# ESP32-H4 register map
Vendor: ESPRESSIF SYSTEMS (SHANGHAI) CO., LTD.; Series: ESP32 H-Series; File version: 1
CPU: RV32IMAC r0p0, little endian, no MPU, no FPU, 0 interrupt priority bits
Address unit: 32 bits
Registers are 32-bit, read-write, reset 0x0 unless marked. A register's access mark holds for its fields unless they carry their own. Offsets are from the block's base; [hi:lo] are bit positions.

## LP_TEE — Low-power Trusted Execution Environment
Base 0x600B1400
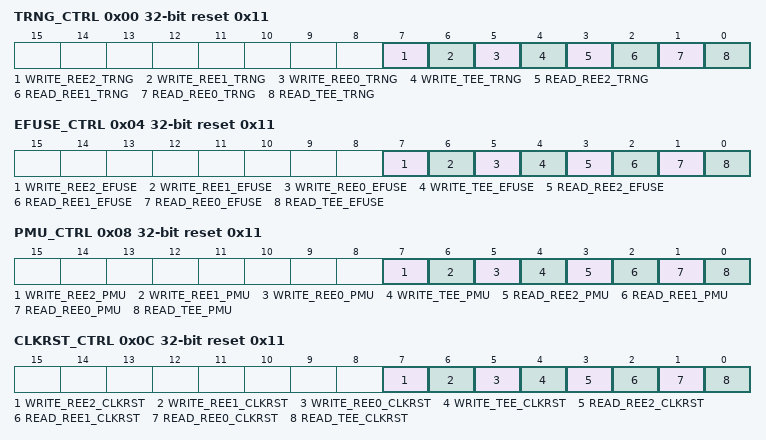
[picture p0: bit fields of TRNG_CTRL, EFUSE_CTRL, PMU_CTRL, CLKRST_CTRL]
0x00 TRNG_CTRL reset 0x11 — trng read/write control register
  [7] WRITE_REE2_TRNG — Configures trng registers write permission in ree2 mode.\\ 0: can not be write \\ 1: can be write \\
  [6] WRITE_REE1_TRNG — Configures trng registers write permission in ree1 mode.\\ 0: can not be write \\ 1: can be write \\
  [5] WRITE_REE0_TRNG — Configures trng registers write permission in ree0 mode.\\ 0: can not be write \\ 1: can be write \\
  [4] WRITE_TEE_TRNG — Configures trng registers write permission in tee mode.\\ 0: can not be write \\ 1: can be write \\
  [3] READ_REE2_TRNG — Configures trng registers read permission in ree2 mode.\\ 0: can not be read \\ 1: can be read \\
  [2] READ_REE1_TRNG — Configures trng registers read permission in ree1 mode.\\ 0: can not be read \\ 1: can be read \\
  [1] READ_REE0_TRNG — Configures trng registers read permission in ree0 mode.\\ 0: can not be read \\ 1: can be read \\
  [0] READ_TEE_TRNG — Configures trng registers read permission in tee mode.\\ 0: can not be read \\ 1: can be read \\
0x04 EFUSE_CTRL reset 0x11 — efuse read/write control register
  [7] WRITE_REE2_EFUSE — Configures efuse registers write permission in ree2 mode.\\ 0: can not be write \\ 1: can be write \\
  [6] WRITE_REE1_EFUSE — Configures efuse registers write permission in ree1 mode.\\ 0: can not be write \\ 1: can be write \\
  [5] WRITE_REE0_EFUSE — Configures efuse registers write permission in ree0 mode.\\ 0: can not be write \\ 1: can be write \\
  [4] WRITE_TEE_EFUSE — Configures efuse registers write permission in tee mode.\\ 0: can not be write \\ 1: can be write \\
  [3] READ_REE2_EFUSE — Configures efuse registers read permission in ree2 mode.\\ 0: can not be read \\ 1: can be read \\
  [2] READ_REE1_EFUSE — Configures efuse registers read permission in ree1 mode.\\ 0: can not be read \\ 1: can be read \\
  [1] READ_REE0_EFUSE — Configures efuse registers read permission in ree0 mode.\\ 0: can not be read \\ 1: can be read \\
  [0] READ_TEE_EFUSE — Configures efuse registers read permission in tee mode.\\ 0: can not be read \\ 1: can be read \\
0x08 PMU_CTRL reset 0x11 — pmu read/write control register
  [7] WRITE_REE2_PMU — Configures pmu registers write permission in ree2 mode.\\ 0: can not be write \\ 1: can be write \\
  [6] WRITE_REE1_PMU — Configures pmu registers write permission in ree1 mode.\\ 0: can not be write \\ 1: can be write \\
  [5] WRITE_REE0_PMU — Configures pmu registers write permission in ree0 mode.\\ 0: can not be write \\ 1: can be write \\
  [4] WRITE_TEE_PMU — Configures pmu registers write permission in tee mode.\\ 0: can not be write \\ 1: can be write \\
  [3] READ_REE2_PMU — Configures pmu registers read permission in ree2 mode.\\ 0: can not be read \\ 1: can be read \\
  [2] READ_REE1_PMU — Configures pmu registers read permission in ree1 mode.\\ 0: can not be read \\ 1: can be read \\
  [1] READ_REE0_PMU — Configures pmu registers read permission in ree0 mode.\\ 0: can not be read \\ 1: can be read \\
  [0] READ_TEE_PMU — Configures pmu registers read permission in tee mode.\\ 0: can not be read \\ 1: can be read \\
0x0C CLKRST_CTRL reset 0x11 — clkrst read/write control register
  [7] WRITE_REE2_CLKRST — Configures clkrst registers write permission in ree2 mode.\\ 0: can not be write \\ 1: can be write \\
  [6] WRITE_REE1_CLKRST — Configures clkrst registers write permission in ree1 mode.\\ 0: can not be write \\ 1: can be write \\
  [5] WRITE_REE0_CLKRST — Configures clkrst registers write permission in ree0 mode.\\ 0: can not be write \\ 1: can be write \\
  [4] WRITE_TEE_CLKRST — Configures clkrst registers write permission in tee mode.\\ 0: can not be write \\ 1: can be write \\
  [3] READ_REE2_CLKRST — Configures clkrst registers read permission in ree2 mode.\\ 0: can not be read \\ 1: can be read \\
  [2] READ_REE1_CLKRST — Configures clkrst registers read permission in ree1 mode.\\ 0: can not be read \\ 1: can be read \\
  [1] READ_REE0_CLKRST — Configures clkrst registers read permission in ree0 mode.\\ 0: can not be read \\ 1: can be read \\
  [0] READ_TEE_CLKRST — Configures clkrst registers read permission in tee mode.\\ 0: can not be read \\ 1: can be read \\
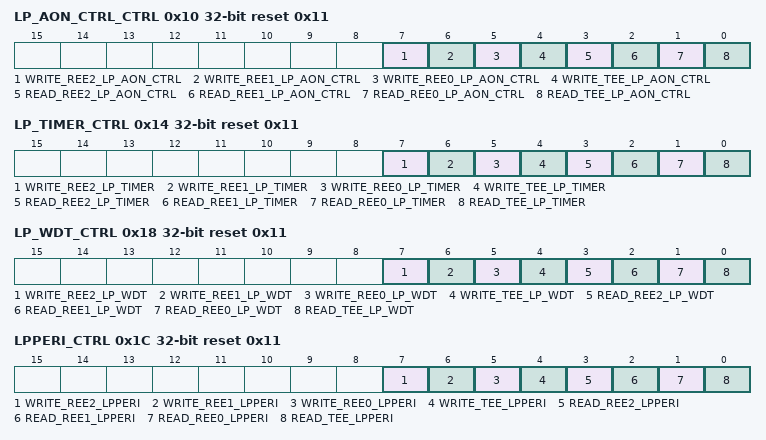
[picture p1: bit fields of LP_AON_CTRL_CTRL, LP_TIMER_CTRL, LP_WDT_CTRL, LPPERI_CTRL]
0x10 LP_AON_CTRL_CTRL reset 0x11 — lp_aon_ctrl read/write control register
  [7] WRITE_REE2_LP_AON_CTRL — Configures lp_aon_ctrl registers write permission in ree2 mode.\\ 0: can not be write \\ 1: can be write \\
  [6] WRITE_REE1_LP_AON_CTRL — Configures lp_aon_ctrl registers write permission in ree1 mode.\\ 0: can not be write \\ 1: can be write \\
  [5] WRITE_REE0_LP_AON_CTRL — Configures lp_aon_ctrl registers write permission in ree0 mode.\\ 0: can not be write \\ 1: can be write \\
  [4] WRITE_TEE_LP_AON_CTRL — Configures lp_aon_ctrl registers write permission in tee mode.\\ 0: can not be write \\ 1: can be write \\
  [3] READ_REE2_LP_AON_CTRL — Configures lp_aon_ctrl registers read permission in ree2 mode.\\ 0: can not be read \\ 1: can be read \\
  [2] READ_REE1_LP_AON_CTRL — Configures lp_aon_ctrl registers read permission in ree1 mode.\\ 0: can not be read \\ 1: can be read \\
  [1] READ_REE0_LP_AON_CTRL — Configures lp_aon_ctrl registers read permission in ree0 mode.\\ 0: can not be read \\ 1: can be read \\
  [0] READ_TEE_LP_AON_CTRL — Configures lp_aon_ctrl registers read permission in tee mode.\\ 0: can not be read \\ 1: can be read \\
0x14 LP_TIMER_CTRL reset 0x11 — lp_timer read/write control register
  [7] WRITE_REE2_LP_TIMER — Configures lp_timer registers write permission in ree2 mode.\\ 0: can not be write \\ 1: can be write \\
  [6] WRITE_REE1_LP_TIMER — Configures lp_timer registers write permission in ree1 mode.\\ 0: can not be write \\ 1: can be write \\
  [5] WRITE_REE0_LP_TIMER — Configures lp_timer registers write permission in ree0 mode.\\ 0: can not be write \\ 1: can be write \\
  [4] WRITE_TEE_LP_TIMER — Configures lp_timer registers write permission in tee mode.\\ 0: can not be write \\ 1: can be write \\
  [3] READ_REE2_LP_TIMER — Configures lp_timer registers read permission in ree2 mode.\\ 0: can not be read \\ 1: can be read \\
  [2] READ_REE1_LP_TIMER — Configures lp_timer registers read permission in ree1 mode.\\ 0: can not be read \\ 1: can be read \\
  [1] READ_REE0_LP_TIMER — Configures lp_timer registers read permission in ree0 mode.\\ 0: can not be read \\ 1: can be read \\
  [0] READ_TEE_LP_TIMER — Configures lp_timer registers read permission in tee mode.\\ 0: can not be read \\ 1: can be read \\
0x18 LP_WDT_CTRL reset 0x11 — lp_wdt read/write control register
  [7] WRITE_REE2_LP_WDT — Configures lp_wdt registers write permission in ree2 mode.\\ 0: can not be write \\ 1: can be write \\
  [6] WRITE_REE1_LP_WDT — Configures lp_wdt registers write permission in ree1 mode.\\ 0: can not be write \\ 1: can be write \\
  [5] WRITE_REE0_LP_WDT — Configures lp_wdt registers write permission in ree0 mode.\\ 0: can not be write \\ 1: can be write \\
  [4] WRITE_TEE_LP_WDT — Configures lp_wdt registers write permission in tee mode.\\ 0: can not be write \\ 1: can be write \\
  [3] READ_REE2_LP_WDT — Configures lp_wdt registers read permission in ree2 mode.\\ 0: can not be read \\ 1: can be read \\
  [2] READ_REE1_LP_WDT — Configures lp_wdt registers read permission in ree1 mode.\\ 0: can not be read \\ 1: can be read \\
  [1] READ_REE0_LP_WDT — Configures lp_wdt registers read permission in ree0 mode.\\ 0: can not be read \\ 1: can be read \\
  [0] READ_TEE_LP_WDT — Configures lp_wdt registers read permission in tee mode.\\ 0: can not be read \\ 1: can be read \\
0x1C LPPERI_CTRL reset 0x11 — lpperi read/write control register
  [7] WRITE_REE2_LPPERI — Configures lpperi registers write permission in ree2 mode.\\ 0: can not be write \\ 1: can be write \\
  [6] WRITE_REE1_LPPERI — Configures lpperi registers write permission in ree1 mode.\\ 0: can not be write \\ 1: can be write \\
  [5] WRITE_REE0_LPPERI — Configures lpperi registers write permission in ree0 mode.\\ 0: can not be write \\ 1: can be write \\
  [4] WRITE_TEE_LPPERI — Configures lpperi registers write permission in tee mode.\\ 0: can not be write \\ 1: can be write \\
  [3] READ_REE2_LPPERI — Configures lpperi registers read permission in ree2 mode.\\ 0: can not be read \\ 1: can be read \\
  [2] READ_REE1_LPPERI — Configures lpperi registers read permission in ree1 mode.\\ 0: can not be read \\ 1: can be read \\
  [1] READ_REE0_LPPERI — Configures lpperi registers read permission in ree0 mode.\\ 0: can not be read \\ 1: can be read \\
  [0] READ_TEE_LPPERI — Configures lpperi registers read permission in tee mode.\\ 0: can not be read \\ 1: can be read \\
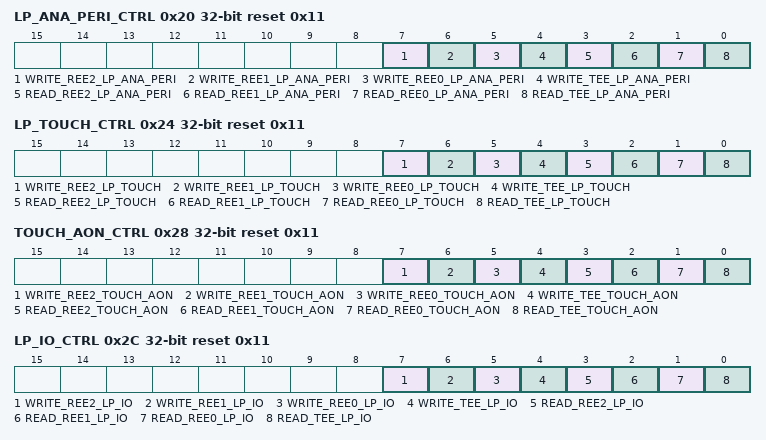
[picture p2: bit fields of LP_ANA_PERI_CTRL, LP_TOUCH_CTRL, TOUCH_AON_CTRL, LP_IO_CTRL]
0x20 LP_ANA_PERI_CTRL reset 0x11 — lp_ana_peri read/write control register
  [7] WRITE_REE2_LP_ANA_PERI — Configures lp_ana_peri registers write permission in ree2 mode.\\ 0: can not be write \\ 1: can be write \\
  [6] WRITE_REE1_LP_ANA_PERI — Configures lp_ana_peri registers write permission in ree1 mode.\\ 0: can not be write \\ 1: can be write \\
  [5] WRITE_REE0_LP_ANA_PERI — Configures lp_ana_peri registers write permission in ree0 mode.\\ 0: can not be write \\ 1: can be write \\
  [4] WRITE_TEE_LP_ANA_PERI — Configures lp_ana_peri registers write permission in tee mode.\\ 0: can not be write \\ 1: can be write \\
  [3] READ_REE2_LP_ANA_PERI — Configures lp_ana_peri registers read permission in ree2 mode.\\ 0: can not be read \\ 1: can be read \\
  [2] READ_REE1_LP_ANA_PERI — Configures lp_ana_peri registers read permission in ree1 mode.\\ 0: can not be read \\ 1: can be read \\
  [1] READ_REE0_LP_ANA_PERI — Configures lp_ana_peri registers read permission in ree0 mode.\\ 0: can not be read \\ 1: can be read \\
  [0] READ_TEE_LP_ANA_PERI — Configures lp_ana_peri registers read permission in tee mode.\\ 0: can not be read \\ 1: can be read \\
0x24 LP_TOUCH_CTRL reset 0x11 — lp_touch read/write control register
  [7] WRITE_REE2_LP_TOUCH — Configures lp_touch registers write permission in ree2 mode.\\ 0: can not be write \\ 1: can be write \\
  [6] WRITE_REE1_LP_TOUCH — Configures lp_touch registers write permission in ree1 mode.\\ 0: can not be write \\ 1: can be write \\
  [5] WRITE_REE0_LP_TOUCH — Configures lp_touch registers write permission in ree0 mode.\\ 0: can not be write \\ 1: can be write \\
  [4] WRITE_TEE_LP_TOUCH — Configures lp_touch registers write permission in tee mode.\\ 0: can not be write \\ 1: can be write \\
  [3] READ_REE2_LP_TOUCH — Configures lp_touch registers read permission in ree2 mode.\\ 0: can not be read \\ 1: can be read \\
  [2] READ_REE1_LP_TOUCH — Configures lp_touch registers read permission in ree1 mode.\\ 0: can not be read \\ 1: can be read \\
  [1] READ_REE0_LP_TOUCH — Configures lp_touch registers read permission in ree0 mode.\\ 0: can not be read \\ 1: can be read \\
  [0] READ_TEE_LP_TOUCH — Configures lp_touch registers read permission in tee mode.\\ 0: can not be read \\ 1: can be read \\
0x28 TOUCH_AON_CTRL reset 0x11 — touch_aon read/write control register
  [7] WRITE_REE2_TOUCH_AON — Configures touch_aon registers write permission in ree2 mode.\\ 0: can not be write \\ 1: can be write \\
  [6] WRITE_REE1_TOUCH_AON — Configures touch_aon registers write permission in ree1 mode.\\ 0: can not be write \\ 1: can be write \\
  [5] WRITE_REE0_TOUCH_AON — Configures touch_aon registers write permission in ree0 mode.\\ 0: can not be write \\ 1: can be write \\
  [4] WRITE_TEE_TOUCH_AON — Configures touch_aon registers write permission in tee mode.\\ 0: can not be write \\ 1: can be write \\
  [3] READ_REE2_TOUCH_AON — Configures touch_aon registers read permission in ree2 mode.\\ 0: can not be read \\ 1: can be read \\
  [2] READ_REE1_TOUCH_AON — Configures touch_aon registers read permission in ree1 mode.\\ 0: can not be read \\ 1: can be read \\
  [1] READ_REE0_TOUCH_AON — Configures touch_aon registers read permission in ree0 mode.\\ 0: can not be read \\ 1: can be read \\
  [0] READ_TEE_TOUCH_AON — Configures touch_aon registers read permission in tee mode.\\ 0: can not be read \\ 1: can be read \\
0x2C LP_IO_CTRL reset 0x11 — lp_io read/write control register
  [7] WRITE_REE2_LP_IO — Configures lp_io registers write permission in ree2 mode.\\ 0: can not be write \\ 1: can be write \\
  [6] WRITE_REE1_LP_IO — Configures lp_io registers write permission in ree1 mode.\\ 0: can not be write \\ 1: can be write \\
  [5] WRITE_REE0_LP_IO — Configures lp_io registers write permission in ree0 mode.\\ 0: can not be write \\ 1: can be write \\
  [4] WRITE_TEE_LP_IO — Configures lp_io registers write permission in tee mode.\\ 0: can not be write \\ 1: can be write \\
  [3] READ_REE2_LP_IO — Configures lp_io registers read permission in ree2 mode.\\ 0: can not be read \\ 1: can be read \\
  [2] READ_REE1_LP_IO — Configures lp_io registers read permission in ree1 mode.\\ 0: can not be read \\ 1: can be read \\
  [1] READ_REE0_LP_IO — Configures lp_io registers read permission in ree0 mode.\\ 0: can not be read \\ 1: can be read \\
  [0] READ_TEE_LP_IO — Configures lp_io registers read permission in tee mode.\\ 0: can not be read \\ 1: can be read \\
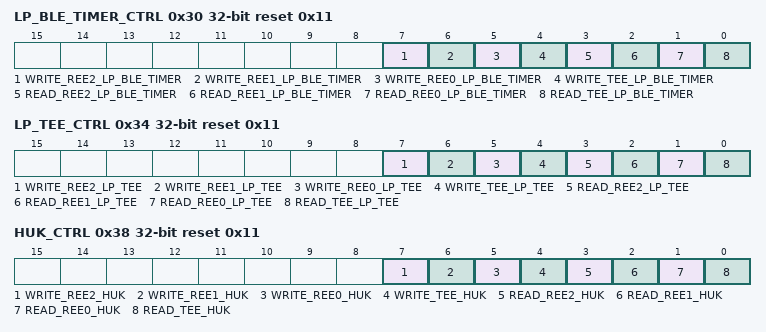
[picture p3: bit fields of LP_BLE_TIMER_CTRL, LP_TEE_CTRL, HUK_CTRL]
0x30 LP_BLE_TIMER_CTRL reset 0x11 — lp_ble_timer read/write control register
  [7] WRITE_REE2_LP_BLE_TIMER — Configures lp_ble_timer registers write permission in ree2 mode.\\ 0: can not be write \\ 1: can be write \\
  [6] WRITE_REE1_LP_BLE_TIMER — Configures lp_ble_timer registers write permission in ree1 mode.\\ 0: can not be write \\ 1: can be write \\
  [5] WRITE_REE0_LP_BLE_TIMER — Configures lp_ble_timer registers write permission in ree0 mode.\\ 0: can not be write \\ 1: can be write \\
  [4] WRITE_TEE_LP_BLE_TIMER — Configures lp_ble_timer registers write permission in tee mode.\\ 0: can not be write \\ 1: can be write \\
  [3] READ_REE2_LP_BLE_TIMER — Configures lp_ble_timer registers read permission in ree2 mode.\\ 0: can not be read \\ 1: can be read \\
  [2] READ_REE1_LP_BLE_TIMER — Configures lp_ble_timer registers read permission in ree1 mode.\\ 0: can not be read \\ 1: can be read \\
  [1] READ_REE0_LP_BLE_TIMER — Configures lp_ble_timer registers read permission in ree0 mode.\\ 0: can not be read \\ 1: can be read \\
  [0] READ_TEE_LP_BLE_TIMER — Configures lp_ble_timer registers read permission in tee mode.\\ 0: can not be read \\ 1: can be read \\
0x34 LP_TEE_CTRL access per field reset 0x11 — lp_tee read/write control register
  [7] WRITE_REE2_LP_TEE ro — Configures lp_tee registers write permission in ree2 mode.\\ 0: can not be write \\ 1: can be write \\
  [6] WRITE_REE1_LP_TEE ro — Configures lp_tee registers write permission in ree1 mode.\\ 0: can not be write \\ 1: can be write \\
  [5] WRITE_REE0_LP_TEE ro — Configures lp_tee registers write permission in ree0 mode.\\ 0: can not be write \\ 1: can be write \\
  [4] WRITE_TEE_LP_TEE rw — Configures lp_tee registers write permission in tee mode.\\ 0: can not be write \\ 1: can be write \\
  [3] READ_REE2_LP_TEE ro — Configures lp_tee registers read permission in ree2 mode.\\ 0: can not be read \\ 1: can be read \\
  [2] READ_REE1_LP_TEE ro — Configures lp_tee registers read permission in ree1 mode.\\ 0: can not be read \\ 1: can be read \\
  [1] READ_REE0_LP_TEE ro — Configures lp_tee registers read permission in ree0 mode.\\ 0: can not be read \\ 1: can be read \\
  [0] READ_TEE_LP_TEE rw — Configures lp_tee registers read permission in tee mode.\\ 0: can not be read \\ 1: can be read \\
0x38 HUK_CTRL reset 0x11 — lp_tee read/write control register
  [7] WRITE_REE2_HUK — Configures huk registers write permission in ree2 mode.\\ 0: can not be write \\ 1: can be write \\
  [6] WRITE_REE1_HUK — Configures huk registers write permission in ree1 mode.\\ 0: can not be write \\ 1: can be write \\
  [5] WRITE_REE0_HUK — Configures huk registers write permission in ree0 mode.\\ 0: can not be write \\ 1: can be write \\
  [4] WRITE_TEE_HUK — Configures huk registers write permission in tee mode.\\ 0: can not be write \\ 1: can be write \\
  [3] READ_REE2_HUK — Configures huk registers read permission in ree2 mode.\\ 0: can not be read \\ 1: can be read \\
  [2] READ_REE1_HUK — Configures huk registers read permission in ree1 mode.\\ 0: can not be read \\ 1: can be read \\
  [1] READ_REE0_HUK — Configures huk registers read permission in ree0 mode.\\ 0: can not be read \\ 1: can be read \\
  [0] READ_TEE_HUK — Configures huk registers read permission in tee mode.\\ 0: can not be read \\ 1: can be read \\
0xE4 LP_GPIO_SECURITY — need des
  [5:0] LP_GPIO_LOCK — This field decides whether lp_gpio_config can be locked, or not. 0 (default): unlocked. 1: locked.
0xE8 HP_GPIO_SECURITY_1 — need des
  [31:0] HP_GPIO_LOCK_P1 — This field decides whether hp_gpio_config of PIN0~31 can be locked, or not. 0 (default): unlocked. 1: locked.
0xEC HP_GPIO_SECURITY_2 — need des
  [7:0] HP_GPIO_LOCK_P2 — This field decides whether hp_gpio_config of PIN32~39 can be locked, or not. 0 (default): unlocked. 1: locked.
0xF0 BUS_ERR_CONF — Clock gating register
  [0] BUS_ERR_RESP_EN — Configures whether return error response to cpu when access blocked 0: disable error response \\ 1: enable error response \\
0xF8 CLOCK_GATE reset 0x1 — Clock gating register
  [0] CLK_EN — Configures whether to keep the clock always on.\\ 0: enable automatic clock gating \\ 1: keep the clock always on \\
0xFC DATE reset 0x2504090 — Version control register
  [27:0] DATE
